AUTOSAR XML (schema 4-0-3)
package /ComponentTypes
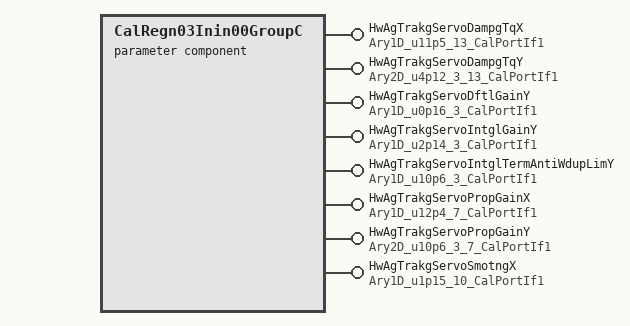
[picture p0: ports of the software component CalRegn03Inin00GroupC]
  parameter sw component type CalRegn03Inin00GroupC
    8 x provide port:
      HwAgTrakgServoDampgTqX: parameter-provide-com-spec{init-value=[0, 1600, 3200, 5362, 5630, 6032, 6434, 6970, 7372, 8310, 10724, 12064, 13404], parameter=Ary1D}, provided-interface=Ary1D_u11p5_13_CalPortIf1
      HwAgTrakgServoDampgTqY: parameter-provide-com-spec{init-value=[[0, 1434, 2867, 4804, 5097, 5593, 6175, 6961, 7595, 8982, 12135, 13677, 15082], [0, 1434, 2867, 4804, 5097, 5593, 6175, 6961, 7595, 8982, 12135, 13677, 15082], [0, 1434, 2867, 4804, 5097, 5593, 6175, 6961, 7595, 8982, 12135, 13677, 15082]], parameter=Ary2D}, provided-interface=Ary2D_u4p12_3_13_CalPortIf1
      HwAgTrakgServoDftlGainY: parameter-provide-com-spec{init-value=[393, 393, 393], parameter=Ary1D}, provided-interface=Ary1D_u0p16_3_CalPortIf1
      HwAgTrakgServoIntglGainY: parameter-provide-com-spec{init-value=[4915, 4915, 4915], parameter=Ary1D}, provided-interface=Ary1D_u2p14_3_CalPortIf1
      HwAgTrakgServoIntglTermAntiWdupLimY: parameter-provide-com-spec{init-value=[128, 96, 64], parameter=Ary1D}, provided-interface=Ary1D_u10p6_3_CalPortIf1
      HwAgTrakgServoPropGainX: parameter-provide-com-spec{init-value=[0, 32, 64, 128, 320, 400, 480], parameter=Ary1D}, provided-interface=Ary1D_u12p4_7_CalPortIf1
      HwAgTrakgServoPropGainY: parameter-provide-com-spec{init-value=[[0, 6, 16, 47, 179, 205, 208], [0, 6, 16, 47, 179, 205, 208], [0, 6, 16, 47, 179, 205, 208]], parameter=Ary2D}, provided-interface=Ary2D_u10p6_3_7_CalPortIf1
      HwAgTrakgServoSmotngX: parameter-provide-com-spec{init-value=[0, 3277, 6554, 9830, 13107, 19661, 22938, 26214, 29491, 32768], parameter=Ary1D}, provided-interface=Ary1D_u1p15_10_CalPortIf1
